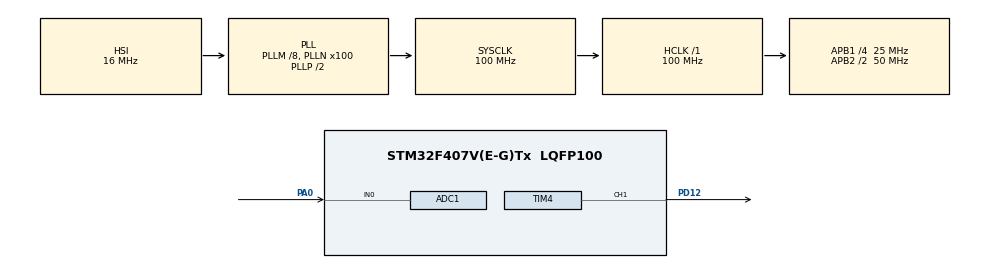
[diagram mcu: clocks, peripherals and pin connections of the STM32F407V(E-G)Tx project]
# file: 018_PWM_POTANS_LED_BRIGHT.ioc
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ADC1.Channel-0\#ChannelRegularConversion=ADC_CHANNEL_0
ADC1.ContinuousConvMode=ENABLE
ADC1.NbrOfConversionFlag=1
ADC1.Rank-0\#ChannelRegularConversion=1
ADC1.SamplingTime-0\#ChannelRegularConversion=ADC_SAMPLETIME_3CYCLES
ADC1.master=1
Mcu.Family=STM32F4
Mcu.Name=STM32F407V(E-G)Tx
Mcu.Package=LQFP100
NVIC.PriorityGroup=NVIC_PRIORITYGROUP_4
PA0-WKUP.Signal=ADCx_IN0
PD12.Signal=S_TIM4_CH1
ProjectManager.HeapSize=0x200
ProjectManager.StackSize=0x400
ProjectManager.TargetToolchain=STM32CubeIDE
RCC.48MHZClocksFreq_Value=50000000
RCC.AHBFreq_Value=100000000
RCC.APB1CLKDivider=RCC_HCLK_DIV4
RCC.APB1Freq_Value=25000000
RCC.APB1TimFreq_Value=50000000
RCC.APB2CLKDivider=RCC_HCLK_DIV2
RCC.APB2Freq_Value=50000000
RCC.APB2TimFreq_Value=100000000
RCC.CortexFreq_Value=100000000
RCC.HCLKFreq_Value=100000000
RCC.HSE_VALUE=25000000
RCC.HSI_VALUE=16000000
RCC.LSE_VALUE=32768
RCC.PLLM=8
RCC.PLLN=100
RCC.SYSCLKFreq_VALUE=100000000
RCC.SYSCLKSource=RCC_SYSCLKSOURCE_PLLCLK
RCC.VCOOutputFreq_Value=200000000
SH.ADCx_IN0.0=ADC1_IN0,IN0
SH.S_TIM4_CH1.0=TIM4_CH1,PWM Generation1 CH1
TIM4.Channel-PWM\ Generation1\ CH1=TIM_CHANNEL_1
TIM4.Period=99
TIM4.Prescaler=499
board=custom

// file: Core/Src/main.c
/* USER CODE BEGIN Header */
/**
  ******************************************************************************
  * @file           : main.c
  * @brief          : Main program body
  ******************************************************************************
  * @attention
  *
  * Copyright (c) 2024 STMicroelectronics.
  * All rights reserved.
  *
  * This software is licensed under terms that can be found in the LICENSE file
  * in the root directory of this software component.
  * If no LICENSE file comes with this software, it is provided AS-IS.
  *
  ******************************************************************************
  */
/* USER CODE END Header */
#include "main.h"

ADC_HandleTypeDef hadc1;

TIM_HandleTypeDef htim4;

/* USER CODE BEGIN PV */
uint16_t adc_value;//1. Step. Okuyacagim adc degerini tutacak degisken
uint16_t pulse;//2.Step. Map degerini tutacak degisken (0 99)

/* USER CODE END PV */

void SystemClock_Config(void);
static void MX_GPIO_Init(void);
static void MX_TIM4_Init(void);
static void MX_ADC1_Init(void);

/* USER CODE BEGIN 0 */
void Read_ADC()//3. Step. Potansiyometreden Adc okuma fonksiyoun
{
	HAL_ADC_Start(&hadc1);//4. Step. Adc yi baslatma fonksiyonu
		if(HAL_ADC_PollForConversion(&hadc1, 1000000) == HAL_OK) //5. Step. FLAG kalkti. If == HAL_OK go next step . HAL_ADC_PollForConversion() kullanarak dönüşümün bitmesini bekleyin, bu aşamada kullanıcı, son uygulamasına göre zaman aşımı değerini belirleyebilir.

		{
			adc_value = HAL_ADC_GetValue(&hadc1);//6. Step. Value has been created and assigned to adc_getvalue and reading to value.

		}
		HAL_ADC_Stop(&hadc1);// 7. Step. Stopping to read ADC.

}

uint16_t map(int IN, int INMIN, int INMAX, int OUTMIN, int OUTMAX)//8. Step. Map in icine Giris sinyali ve cikis sinyallerini tanimladi.
{
	return (IN - INMIN)*(OUTMAX-OUTMIN)/(INMAX-INMIN)+OUTMIN;//9. Step. Potansiyometre 0 iken led parlakligi  0. Potansiyometre 4095 iken Led parlakliginin 99 olmasi icin gereken formul.
}
/* USER CODE END 0 */

int main(void)
{

  /* MCU Configuration--------------------------------------------------------*/

  /* Reset of all peripherals, Initializes the Flash interface and the Systick. */
  HAL_Init();

  /* Configure the system clock */
  SystemClock_Config();

  /* Initialize all configured peripherals */
  MX_GPIO_Init();
  MX_TIM4_Init();
  MX_ADC1_Init();
  /* USER CODE BEGIN 2 */

HAL_TIM_PWM_Start(&htim4, TIM_CHANNEL_1);//10. Step. PWM i baslattik.

  /* USER CODE END 2 */

  /* Infinite loop */
  while (1)
  {

    /* USER CODE BEGIN 3 */
	  pulse = map (adc_value, 0, 4095, 0, 99);//11. Step. adc_value degeri potansiyometrenin o anki konumuyla alakali (0 ile 4095) arasinda bir deger. INMIN = 0, INMAX=4095, OUTMIN= 0, OUTMAX= 99, IN = adc_value.

	 		  __HAL_TIM_SET_COMPARE(&htim4, TIM_CHANNEL_1, pulse);//12. Step. pulse degerini PWM e deger olarak  atadik

     Read_ADC();//13. Last Step. Adc okumasini surekli yaptik
  }
  /* USER CODE END 3 */
}

void SystemClock_Config(void)
{
  RCC_OscInitTypeDef RCC_OscInitStruct = {0};
  RCC_ClkInitTypeDef RCC_ClkInitStruct = {0};

  /** Configure the main internal regulator output voltage
  */
  __HAL_RCC_PWR_CLK_ENABLE();
  __HAL_PWR_VOLTAGESCALING_CONFIG(PWR_REGULATOR_VOLTAGE_SCALE1);

  /** Initializes the RCC Oscillators according to the specified parameters
  * in the RCC_OscInitTypeDef structure.
  */
  RCC_OscInitStruct.OscillatorType = RCC_OSCILLATORTYPE_HSI;
  RCC_OscInitStruct.HSIState = RCC_HSI_ON;
  RCC_OscInitStruct.HSICalibrationValue = RCC_HSICALIBRATION_DEFAULT;
  RCC_OscInitStruct.PLL.PLLState = RCC_PLL_ON;
  RCC_OscInitStruct.PLL.PLLSource = RCC_PLLSOURCE_HSI;
  RCC_OscInitStruct.PLL.PLLM = 8;
  RCC_OscInitStruct.PLL.PLLN = 100;
  RCC_OscInitStruct.PLL.PLLP = RCC_PLLP_DIV2;
  RCC_OscInitStruct.PLL.PLLQ = 4;
  if (HAL_RCC_OscConfig(&RCC_OscInitStruct) != HAL_OK)
  {
    Error_Handler();
  }

  /** Initializes the CPU, AHB and APB buses clocks
  */
  RCC_ClkInitStruct.ClockType = RCC_CLOCKTYPE_HCLK|RCC_CLOCKTYPE_SYSCLK
                              |RCC_CLOCKTYPE_PCLK1|RCC_CLOCKTYPE_PCLK2;
  RCC_ClkInitStruct.SYSCLKSource = RCC_SYSCLKSOURCE_PLLCLK;
  RCC_ClkInitStruct.AHBCLKDivider = RCC_SYSCLK_DIV1;
  RCC_ClkInitStruct.APB1CLKDivider = RCC_HCLK_DIV4;
  RCC_ClkInitStruct.APB2CLKDivider = RCC_HCLK_DIV2;

  if (HAL_RCC_ClockConfig(&RCC_ClkInitStruct, FLASH_LATENCY_3) != HAL_OK)
  {
    Error_Handler();
  }
}

static void MX_ADC1_Init(void)
{

  ADC_ChannelConfTypeDef sConfig = {0};

  /** Configure the global features of the ADC (Clock, Resolution, Data Alignment and number of conversion)
  */
  hadc1.Instance = ADC1;
  hadc1.Init.ClockPrescaler = ADC_CLOCK_SYNC_PCLK_DIV2;
  hadc1.Init.Resolution = ADC_RESOLUTION_12B;
  hadc1.Init.ScanConvMode = DISABLE;
  hadc1.Init.ContinuousConvMode = ENABLE;
  hadc1.Init.DiscontinuousConvMode = DISABLE;
  hadc1.Init.ExternalTrigConvEdge = ADC_EXTERNALTRIGCONVEDGE_NONE;
  hadc1.Init.ExternalTrigConv = ADC_SOFTWARE_START;
  hadc1.Init.DataAlign = ADC_DATAALIGN_RIGHT;
  hadc1.Init.NbrOfConversion = 1;
  hadc1.Init.DMAContinuousRequests = DISABLE;
  hadc1.Init.EOCSelection = ADC_EOC_SINGLE_CONV;
  if (HAL_ADC_Init(&hadc1) != HAL_OK)
  {
    Error_Handler();
  }

  /** Configure for the selected ADC regular channel its corresponding rank in the sequencer and its sample time.
  */
  sConfig.Channel = ADC_CHANNEL_0;
  sConfig.Rank = 1;
  sConfig.SamplingTime = ADC_SAMPLETIME_3CYCLES;
  if (HAL_ADC_ConfigChannel(&hadc1, &sConfig) != HAL_OK)
  {
    Error_Handler();
  }

}

static void MX_TIM4_Init(void)
{

  TIM_MasterConfigTypeDef sMasterConfig = {0};
  TIM_OC_InitTypeDef sConfigOC = {0};

  htim4.Instance = TIM4;
  htim4.Init.Prescaler = 499;
  htim4.Init.CounterMode = TIM_COUNTERMODE_UP;
  htim4.Init.Period = 99;
  htim4.Init.ClockDivision = TIM_CLOCKDIVISION_DIV1;
  htim4.Init.AutoReloadPreload = TIM_AUTORELOAD_PRELOAD_DISABLE;
  if (HAL_TIM_PWM_Init(&htim4) != HAL_OK)
  {
    Error_Handler();
  }
  sMasterConfig.MasterOutputTrigger = TIM_TRGO_RESET;
  sMasterConfig.MasterSlaveMode = TIM_MASTERSLAVEMODE_DISABLE;
  if (HAL_TIMEx_MasterConfigSynchronization(&htim4, &sMasterConfig) != HAL_OK)
  {
    Error_Handler();
  }
  sConfigOC.OCMode = TIM_OCMODE_PWM1;
  sConfigOC.Pulse = 0;
  sConfigOC.OCPolarity = TIM_OCPOLARITY_HIGH;
  sConfigOC.OCFastMode = TIM_OCFAST_DISABLE;
  if (HAL_TIM_PWM_ConfigChannel(&htim4, &sConfigOC, TIM_CHANNEL_1) != HAL_OK)
  {
    Error_Handler();
  }
  HAL_TIM_MspPostInit(&htim4);

}

static void MX_GPIO_Init(void)
{

  /* GPIO Ports Clock Enable */
  __HAL_RCC_GPIOA_CLK_ENABLE();
  __HAL_RCC_GPIOD_CLK_ENABLE();

}

void Error_Handler(void)
{
  __disable_irq();
  while (1)
  {
  }
}
